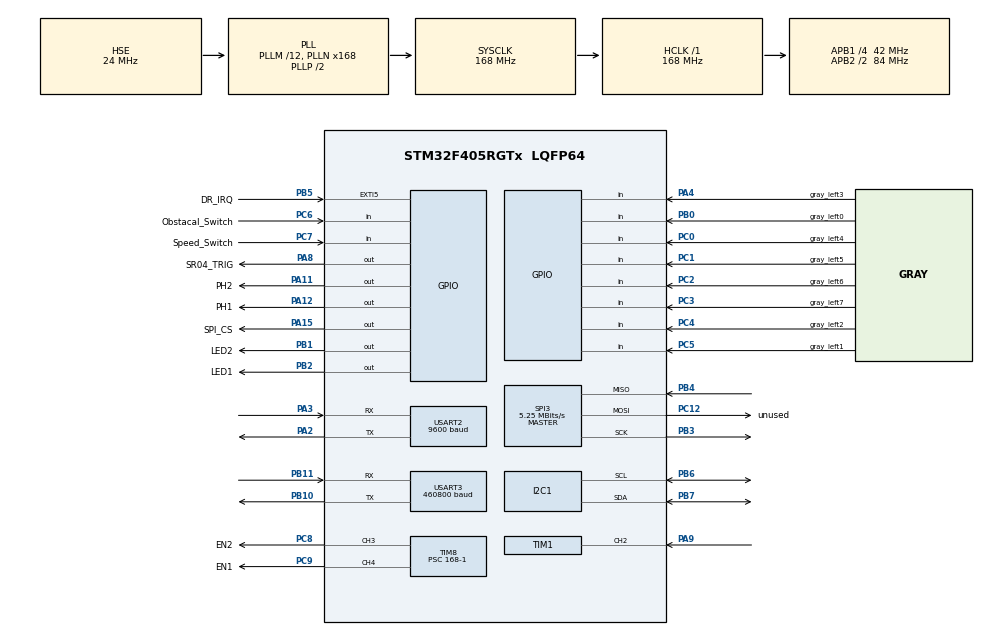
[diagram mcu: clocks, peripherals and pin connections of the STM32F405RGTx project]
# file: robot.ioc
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Dma.Request0=SPI3_RX
Dma.Request1=SPI3_TX
Dma.Request2=USART2_RX
Dma.Request3=USART3_RX
Dma.Request4=USART2_TX
Dma.SPI3_RX.0.Direction=DMA_PERIPH_TO_MEMORY
Dma.SPI3_RX.0.FIFOMode=DMA_FIFOMODE_DISABLE
Dma.SPI3_RX.0.Instance=DMA1_Stream0
Dma.SPI3_RX.0.MemDataAlignment=DMA_MDATAALIGN_BYTE
Dma.SPI3_RX.0.MemInc=DMA_MINC_ENABLE
Dma.SPI3_RX.0.Mode=DMA_NORMAL
Dma.SPI3_RX.0.PeriphDataAlignment=DMA_PDATAALIGN_BYTE
Dma.SPI3_RX.0.PeriphInc=DMA_PINC_DISABLE
Dma.SPI3_RX.0.Priority=DMA_PRIORITY_LOW
Dma.SPI3_TX.1.Direction=DMA_MEMORY_TO_PERIPH
Dma.SPI3_TX.1.FIFOMode=DMA_FIFOMODE_DISABLE
Dma.SPI3_TX.1.Instance=DMA1_Stream7
Dma.SPI3_TX.1.MemDataAlignment=DMA_MDATAALIGN_BYTE
Dma.SPI3_TX.1.MemInc=DMA_MINC_ENABLE
Dma.SPI3_TX.1.Mode=DMA_NORMAL
Dma.SPI3_TX.1.PeriphDataAlignment=DMA_PDATAALIGN_BYTE
Dma.SPI3_TX.1.PeriphInc=DMA_PINC_DISABLE
Dma.SPI3_TX.1.Priority=DMA_PRIORITY_LOW
Dma.USART2_RX.2.Direction=DMA_PERIPH_TO_MEMORY
Dma.USART2_RX.2.FIFOMode=DMA_FIFOMODE_DISABLE
Dma.USART2_RX.2.Instance=DMA1_Stream5
Dma.USART2_RX.2.MemDataAlignment=DMA_MDATAALIGN_BYTE
Dma.USART2_RX.2.MemInc=DMA_MINC_ENABLE
Dma.USART2_RX.2.Mode=DMA_NORMAL
Dma.USART2_RX.2.PeriphDataAlignment=DMA_PDATAALIGN_BYTE
Dma.USART2_RX.2.PeriphInc=DMA_PINC_DISABLE
Dma.USART2_RX.2.Priority=DMA_PRIORITY_LOW
Dma.USART2_TX.4.Direction=DMA_MEMORY_TO_PERIPH
Dma.USART2_TX.4.FIFOMode=DMA_FIFOMODE_DISABLE
Dma.USART2_TX.4.Instance=DMA1_Stream6
Dma.USART2_TX.4.MemDataAlignment=DMA_MDATAALIGN_BYTE
Dma.USART2_TX.4.MemInc=DMA_MINC_ENABLE
Dma.USART2_TX.4.Mode=DMA_NORMAL
Dma.USART2_TX.4.PeriphDataAlignment=DMA_PDATAALIGN_BYTE
Dma.USART2_TX.4.PeriphInc=DMA_PINC_DISABLE
Dma.USART2_TX.4.Priority=DMA_PRIORITY_LOW
Dma.USART3_RX.3.Direction=DMA_PERIPH_TO_MEMORY
Dma.USART3_RX.3.FIFOMode=DMA_FIFOMODE_DISABLE
Dma.USART3_RX.3.Instance=DMA1_Stream1
Dma.USART3_RX.3.MemDataAlignment=DMA_MDATAALIGN_BYTE
Dma.USART3_RX.3.MemInc=DMA_MINC_ENABLE
Dma.USART3_RX.3.Mode=DMA_NORMAL
Dma.USART3_RX.3.PeriphDataAlignment=DMA_PDATAALIGN_BYTE
Dma.USART3_RX.3.PeriphInc=DMA_PINC_DISABLE
Dma.USART3_RX.3.Priority=DMA_PRIORITY_LOW
FREERTOS.Tasks01=defaultTask,24,128,StartDefaultTask,Default,NULL,Dynamic,NULL,NULL
FREERTOS.configENABLE_FPU=1
Mcu.Family=STM32F4
Mcu.Name=STM32F405RGTx
Mcu.Package=LQFP64
NVIC.DMA1_Stream0_IRQn=true\:5\:0\:false\:false\:true\:true\:false\:true\:true
NVIC.DMA1_Stream1_IRQn=true\:5\:0\:false\:false\:true\:true\:false\:true\:true
NVIC.DMA1_Stream5_IRQn=true\:5\:0\:false\:false\:true\:true\:false\:true\:true
NVIC.DMA1_Stream6_IRQn=true\:5\:0\:false\:false\:true\:true\:false\:true\:true
NVIC.DMA1_Stream7_IRQn=true\:5\:0\:false\:false\:true\:false\:false\:true\:true
NVIC.EXTI9_5_IRQn=true\:5\:0\:false\:false\:true\:true\:true\:true\:true
NVIC.PriorityGroup=NVIC_PRIORITYGROUP_4
NVIC.TIM1_BRK_TIM9_IRQn=true\:5\:0\:false\:false\:true\:true\:true\:true\:true
NVIC.TIM1_CC_IRQn=true\:5\:0\:false\:false\:true\:true\:true\:true\:true
NVIC.TIM1_TRG_COM_TIM11_IRQn=true\:5\:0\:false\:false\:true\:true\:true\:true\:true
NVIC.TIM1_UP_TIM10_IRQn=true\:5\:0\:false\:false\:true\:true\:true\:true\:true
NVIC.TIM8_BRK_TIM12_IRQn=true\:5\:0\:false\:false\:true\:true\:true\:true\:true
NVIC.TIM8_TRG_COM_TIM14_IRQn=true\:5\:0\:false\:false\:true\:false\:false\:true\:true
NVIC.TIM8_UP_TIM13_IRQn=true\:5\:0\:false\:false\:true\:true\:true\:true\:true
NVIC.USART2_IRQn=true\:5\:0\:false\:false\:true\:true\:true\:true\:true
NVIC.USART3_IRQn=true\:5\:0\:false\:false\:true\:true\:true\:true\:true
PA11.GPIO_Label=PH2
PA11.Signal=GPIO_Output
PA12.GPIO_Label=PH1
PA12.Signal=GPIO_Output
PA13.Mode=Serial_Wire
PA13.Signal=SYS_JTMS-SWDIO
PA14.Mode=Serial_Wire
PA14.Signal=SYS_JTCK-SWCLK
PA15.GPIO_Label=SPI_CS
PA15.GPIO_PuPd=GPIO_PULLUP
PA15.Signal=GPIO_Output
PA2.Mode=Asynchronous
PA2.Signal=USART2_TX
PA3.Mode=Asynchronous
PA3.Signal=USART2_RX
PA4.GPIO_Label=gray_left3
PA4.GPIO_PuPd=GPIO_PULLDOWN
PA4.Signal=GPIO_Input
PA8.GPIO_Label=SR04_TRIG
PA8.Signal=GPIO_Output
PA9.Signal=S_TIM1_CH2
PB0.GPIO_Label=gray_left0
PB0.GPIO_PuPd=GPIO_PULLDOWN
PB0.Signal=GPIO_Input
PB1.GPIO_Label=LED2
PB1.GPIO_PuPd=GPIO_PULLUP
PB1.Signal=GPIO_Output
PB10.Mode=Asynchronous
PB10.Signal=USART3_TX
PB11.Mode=Asynchronous
PB11.Signal=USART3_RX
PB2.GPIO_Label=LED1
PB2.GPIO_PuPd=GPIO_PULLUP
PB2.Signal=GPIO_Output
PB3.Mode=Full_Duplex_Master
PB3.Signal=SPI3_SCK
PB4.Mode=Full_Duplex_Master
PB4.Signal=SPI3_MISO
PB5.GPIO_Label=DR_IRQ
PB5.GPIO_ModeDefaultEXTI=GPIO_MODE_IT_FALLING
PB5.GPIO_PuPd=GPIO_PULLUP
PB5.Signal=GPXTI5
PB6.Mode=I2C
PB6.Signal=I2C1_SCL
PB7.Mode=I2C
PB7.Signal=I2C1_SDA
PC0.GPIO_Label=gray_left4
PC0.GPIO_PuPd=GPIO_PULLDOWN
PC0.Signal=GPIO_Input
PC1.GPIO_Label=gray_left5
PC1.GPIO_PuPd=GPIO_PULLDOWN
PC1.Signal=GPIO_Input
PC12.GPIO_Label=unused
PC12.Mode=Full_Duplex_Master
PC12.Signal=SPI3_MOSI
PC2.GPIO_Label=gray_left6
PC2.GPIO_PuPd=GPIO_PULLDOWN
PC2.Signal=GPIO_Input
PC3.GPIO_Label=gray_left7
PC3.GPIO_PuPd=GPIO_PULLDOWN
PC3.Signal=GPIO_Input
PC4.GPIO_Label=gray_left2
PC4.GPIO_PuPd=GPIO_PULLDOWN
PC4.Signal=GPIO_Input
PC5.GPIO_Label=gray_left1
PC5.GPIO_PuPd=GPIO_PULLDOWN
PC5.Signal=GPIO_Input
PC6.GPIO_Label=Obstacal_Switch
PC6.GPIO_PuPd=GPIO_PULLDOWN
PC6.Signal=GPIO_Input
PC7.GPIO_Label=Speed_Switch
PC7.GPIO_PuPd=GPIO_PULLDOWN
PC7.Signal=GPIO_Input
PC8.GPIO_Label=EN2
PC8.Signal=S_TIM8_CH3
PC9.GPIO_Label=EN1
PC9.Signal=S_TIM8_CH4
PH0-OSC_IN.Mode=HSE-External-Oscillator
PH0-OSC_IN.Signal=RCC_OSC_IN
PH1-OSC_OUT.Mode=HSE-External-Oscillator
PH1-OSC_OUT.Signal=RCC_OSC_OUT
ProjectManager.HeapSize=0x400
ProjectManager.StackSize=0x400
ProjectManager.TargetToolchain=MDK-ARM V5.32
RCC.48MHZClocksFreq_Value=84000000
RCC.AHBFreq_Value=168000000
RCC.APB1CLKDivider=RCC_HCLK_DIV4
RCC.APB1Freq_Value=42000000
RCC.APB1TimFreq_Value=84000000
RCC.APB2CLKDivider=RCC_HCLK_DIV2
RCC.APB2Freq_Value=84000000
RCC.APB2TimFreq_Value=168000000
RCC.CortexFreq_Value=168000000
RCC.HCLKFreq_Value=168000000
RCC.HSE_VALUE=24000000
RCC.HSI_VALUE=16000000
RCC.LSE_VALUE=32768
RCC.PLLM=12
RCC.PLLN=168
RCC.PLLSourceVirtual=RCC_PLLSOURCE_HSE
RCC.SYSCLKFreq_VALUE=168000000
RCC.SYSCLKSource=RCC_SYSCLKSOURCE_PLLCLK
RCC.VCOOutputFreq_Value=336000000
SH.S_TIM1_CH2.0=TIM1_CH2,Input_Capture2_from_TI2
SH.S_TIM8_CH3.0=TIM8_CH3,PWM Generation3 CH3
SH.S_TIM8_CH4.0=TIM8_CH4,PWM Generation4 CH4
SPI3.BaudRatePrescaler=SPI_BAUDRATEPRESCALER_8
SPI3.CalculateBaudRate=5.25 MBits/s
SPI3.Direction=SPI_DIRECTION_2LINES
SPI3.Mode=SPI_MODE_MASTER
SPI3.VirtualType=VM_MASTER
TIM1.AutoReloadPreload=TIM_AUTORELOAD_PRELOAD_ENABLE
TIM1.Channel-Input_Capture2_from_TI2=TIM_CHANNEL_2
TIM1.Prescaler=168-1
TIM11.AutoReloadPreload=TIM_AUTORELOAD_PRELOAD_ENABLE
TIM11.Period=10-1
TIM11.Prescaler=168-1
TIM12.AutoReloadPreload=TIM_AUTORELOAD_PRELOAD_ENABLE
TIM12.Period=1000-1
TIM12.Prescaler=84-1
TIM13.AutoReloadPreload=TIM_AUTORELOAD_PRELOAD_ENABLE
TIM13.Period=1000-1
TIM13.Prescaler=84-1
TIM8.AutoReloadPreload=TIM_AUTORELOAD_PRELOAD_ENABLE
TIM8.Channel-PWM\ Generation3\ CH3=TIM_CHANNEL_3
TIM8.Channel-PWM\ Generation4\ CH4=TIM_CHANNEL_4
TIM8.Period=100-1
TIM8.Prescaler=168-1
USART2.BaudRate=9600
USART2.VirtualMode=VM_ASYNC
USART3.BaudRate=460800
USART3.VirtualMode=VM_ASYNC
VP_FREERTOS_VS_CMSIS_V2.Mode=CMSIS_V2
VP_TIM11_VS_ClockSourceINT.Mode=Enable_Timer
VP_TIM12_VS_ClockSourceINT.Mode=Internal
VP_TIM13_VS_ClockSourceINT.Mode=Enable_Timer
VP_TIM1_VS_ClockSourceINT.Mode=Internal
board=custom

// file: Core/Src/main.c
/* USER CODE BEGIN Header */
/**
  ******************************************************************************
  * @file           : main.c
  * @brief          : Main program body
  ******************************************************************************
  * @attention
  *
  * Copyright (c) 2025 STMicroelectronics.
  * All rights reserved.
  *
  * This software is licensed under terms that can be found in the LICENSE file
  * in the root directory of this software component.
  * If no LICENSE file comes with this software, it is provided AS-IS.
  *
  ******************************************************************************
  */
/* USER CODE END Header */
#include "main.h"
#include "cmsis_os.h"
#include "dma.h"
#include "i2c.h"
#include "spi.h"
#include "tim.h"
#include "usart.h"
#include "gpio.h"

/* USER CODE BEGIN Includes */
#include "main_rtos.h"
/* USER CODE END Includes */

void SystemClock_Config(void);
void MX_FREERTOS_Init(void);

int main(void)
{

  /* MCU Configuration--------------------------------------------------------*/

  /* Reset of all peripherals, Initializes the Flash interface and the Systick. */
  HAL_Init();

  /* Configure the system clock */
  SystemClock_Config();

  /* Initialize all configured peripherals */
  MX_GPIO_Init();
  MX_DMA_Init();
  MX_TIM8_Init();
  MX_SPI3_Init();
  MX_TIM12_Init();
  MX_TIM13_Init();
  MX_TIM11_Init();
  MX_I2C1_Init();
  MX_USART2_UART_Init();
  MX_USART3_UART_Init();
  MX_TIM1_Init();
  /* USER CODE BEGIN 2 */
//HAL_Delay(2000);
  main_rtos();

  /* USER CODE END 2 */

  /* Init scheduler */
  osKernelInitialize();  /* Call init function for freertos objects (in cmsis_os2.c) */
  MX_FREERTOS_Init();

  /* Start scheduler */
  osKernelStart();

  /* We should never get here as control is now taken by the scheduler */

  /* Infinite loop */
  while (1)
  {

  }
}

void SystemClock_Config(void)
{
  RCC_OscInitTypeDef RCC_OscInitStruct = {0};
  RCC_ClkInitTypeDef RCC_ClkInitStruct = {0};

  /** Configure the main internal regulator output voltage
  */
  __HAL_RCC_PWR_CLK_ENABLE();
  __HAL_PWR_VOLTAGESCALING_CONFIG(PWR_REGULATOR_VOLTAGE_SCALE1);

  /** Initializes the RCC Oscillators according to the specified parameters
  * in the RCC_OscInitTypeDef structure.
  */
  RCC_OscInitStruct.OscillatorType = RCC_OSCILLATORTYPE_HSE;
  RCC_OscInitStruct.HSEState = RCC_HSE_ON;
  RCC_OscInitStruct.PLL.PLLState = RCC_PLL_ON;
  RCC_OscInitStruct.PLL.PLLSource = RCC_PLLSOURCE_HSE;
  RCC_OscInitStruct.PLL.PLLM = 12;
  RCC_OscInitStruct.PLL.PLLN = 168;
  RCC_OscInitStruct.PLL.PLLP = RCC_PLLP_DIV2;
  RCC_OscInitStruct.PLL.PLLQ = 4;
  if (HAL_RCC_OscConfig(&RCC_OscInitStruct) != HAL_OK)
  {
    Error_Handler();
  }

  /** Initializes the CPU, AHB and APB buses clocks
  */
  RCC_ClkInitStruct.ClockType = RCC_CLOCKTYPE_HCLK|RCC_CLOCKTYPE_SYSCLK
                              |RCC_CLOCKTYPE_PCLK1|RCC_CLOCKTYPE_PCLK2;
  RCC_ClkInitStruct.SYSCLKSource = RCC_SYSCLKSOURCE_PLLCLK;
  RCC_ClkInitStruct.AHBCLKDivider = RCC_SYSCLK_DIV1;
  RCC_ClkInitStruct.APB1CLKDivider = RCC_HCLK_DIV4;
  RCC_ClkInitStruct.APB2CLKDivider = RCC_HCLK_DIV2;

  if (HAL_RCC_ClockConfig(&RCC_ClkInitStruct, FLASH_LATENCY_5) != HAL_OK)
  {
    Error_Handler();
  }
}

void Error_Handler(void)
{
  __disable_irq();
  while (1)
  {
  }
}
